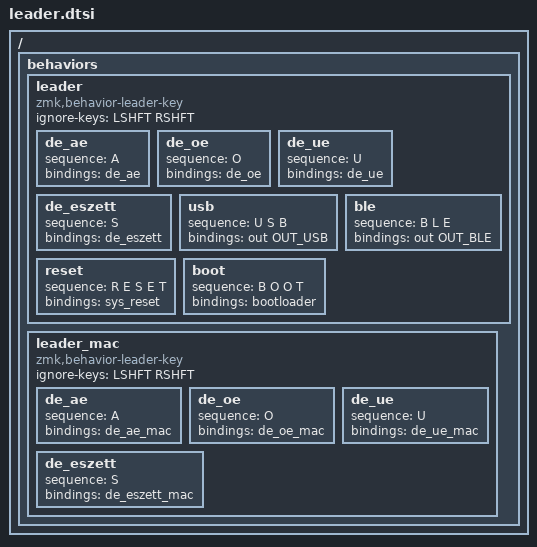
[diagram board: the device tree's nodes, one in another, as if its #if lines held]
/ {
    behaviors {
        leader: leader {
            compatible = "zmk,behavior-leader-key";
            #binding-cells = <0>;
            ignore-keys = <LSHFT RSHFT>;
            de_ae { sequence = <A>; bindings = <&de_ae>; };
            de_oe { sequence = <O>; bindings = <&de_oe>; };
            de_ue { sequence = <U>; bindings = <&de_ue>; };
            de_eszett { sequence = <S>; bindings = <&de_eszett>; };
#ifdef CONFIG_WIRELESS
            usb { sequence = <U S B>; bindings = <&out OUT_USB>; };
            ble { sequence = <B L E>; bindings = <&out OUT_BLE>; };
#endif
            reset { sequence = <R E S E T>; bindings = <&sys_reset>; };
            boot { sequence = <B O O T>; bindings = <&bootloader>; };
        };

        leader_mac: leader_mac {
            compatible = "zmk,behavior-leader-key";
            #binding-cells = <0>;
            ignore-keys = <LSHFT RSHFT>;
            de_ae { sequence = <A>; bindings = <&de_ae_mac>; };
            de_oe { sequence = <O>; bindings = <&de_oe_mac>; };
            de_ue { sequence = <U>; bindings = <&de_ue_mac>; };
            de_eszett { sequence = <S>; bindings = <&de_eszett_mac>; };
        };
    };
};
